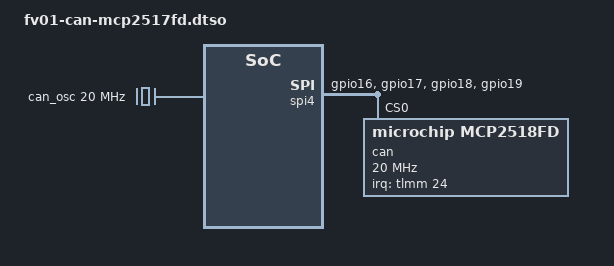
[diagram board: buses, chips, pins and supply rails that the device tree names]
/dts-v1/;
/plugin/;

/*
 * FV01 CAN Transceiver Overlay (QUP0_SE4 SPI @ 0x990000 + MCP2517FD/MCP2518FD)
 * Enables spi@990000 in FIFO/IRQ mode on TLMM GPIO 16..19 with 20 MHz
 * external oscillator and TLMM GPIO 24 falling-edge IRQ.
 * Qualcomm 40-Pin Header Pins 37/39 expose CAN_L / CAN_H transceiver bus lines.
 *
 * TrustZone / Open-FW EL2 Security & Hardware Population Note:
 * - On factory OEM EL1 TZ firmware, QUP0_SE4 (`0x990000`) was XPU-locked to
 *   `trusted-touch-io-bases` and triggered an immediate reset when accessed.
 * - Under Open-FW EL2 (TF-A BL31 `QTI_XPU_BYPASS` + Linux `qupv3fw.elf`),
 *   `spi@990000` is unlocked and completes native GENI SPI transfers cleanly.
 * - Keep this overlay separate from base `qcs6490-fv01-el2.dtb` because base
 *   A6490PF1 boards without an onboard MCP2517FD/18FD populated return
 *   `osc=0xffffffff` (-ENODEV) on `spi4.0`.
 */

&{/} {
	can_osc: can-oscillator {
		compatible = "fixed-clock";
		#clock-cells = <0>;
		clock-frequency = <20000000>;
	};
};

&tlmm {
	qup_spi4_fv01_active: qup-spi4-fv01-active-state {
		pins = "gpio16", "gpio17", "gpio18", "gpio19";
		function = "qup04";
		drive-strength = <6>;
		bias-disable;
	};

	can_irq_state: can-irq-state {
		pins = "gpio24";
		function = "gpio";
		input-enable;
		bias-pull-up;
		drive-strength = <2>;
	};
};

&spi4 {
	pinctrl-names = "default";
	pinctrl-0 = <&qup_spi4_fv01_active>;
	#address-cells = <1>;
	#size-cells = <0>;
	status = "okay";

	can@0 {
		compatible = "microchip,mcp2518fd", "microchip,mcp2517fd";
		reg = <0>;
		clocks = <&can_osc>;
		pinctrl-names = "default";
		pinctrl-0 = <&can_irq_state>;
		interrupts-extended = <&tlmm 24 2>;
		spi-max-frequency = <20000000>;
	};
};
